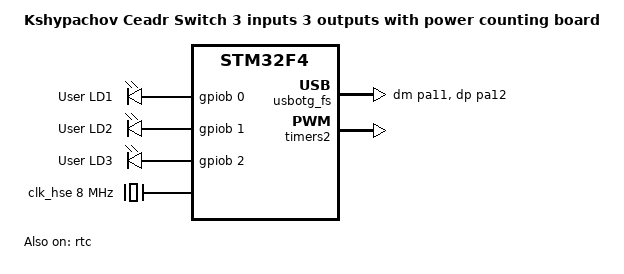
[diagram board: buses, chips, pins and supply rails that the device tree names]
/*
 * Copyright (c) 2017 Florian Vaussard, HEIG-VD
 *
 * SPDX-License-Identifier: Apache-2.0
 */

/dts-v1/;
#include <st/f4/stm32f411xe.dtsi>
#include <st/f4/stm32f411c(c-e)ux-pinctrl.dtsi>
//#include "arduino_r3_connector.dtsi"
#include <zephyr/dt-bindings/input/input-event-codes.h>

/ {
	model = "Kshypachov Ceadr Switch 3 inputs 3 outputs with power counting board";
	compatible = "kshypachov,cedar-switch-3in3out-power", "st,stm32f411ce", "st,stm32f4";

	chosen {
//		zephyr,console = &usart3;
//		zephyr,shell-uart = &usart3;
		zephyr,sram = &sram0;
		zephyr,flash = &flash0;
	};

	leds: leds {
		compatible = "gpio-leds";

		green_led_1: led_1 {
			gpios = <&gpiob 0 GPIO_ACTIVE_HIGH>;
			label = "User LD1";
		};

		blue_led_1: led_2 {
			gpios = <&gpiob 1 GPIO_ACTIVE_HIGH>;
			label = "User LD2";
		};

		red_led_1: led_3 {
			gpios = <&gpiob 2 GPIO_ACTIVE_HIGH>;
			label = "User LD3";
		};
	};

	aliases {
		led0 = &green_led_1;
		led1 = &blue_led_1;
		led2 = &red_led_1;
	};

};


//&spi2 {
//	status = "okay";
//	cs-gpios = <&gpiob 12 GPIO_ACTIVE_LOW>, <&gpioa 9 GPIO_ACTIVE_LOW>;
//	pinctrl-0 = <&spi2_sck_pb13 &spi2_miso_pb14 &spi2_mosi_pb15>;
//	pinctrl-names = "default";
//
//	w5500@0 {
//		compatible = "wiznet,w5500";
//		reg = <0>;
//		label = "ETH_W5500";
//		spi-max-frequency = <8000000>;
//		reset-gpios = <&gpioa 10 GPIO_ACTIVE_LOW>;
//		int-gpios = <&gpioa 0 GPIO_ACTIVE_LOW>;
//	};
//
//	flash@1 {
//		compatible = "jedec,spi-nor";
//		reg = <1>;
//		label = "W25Q64";
//		spi-max-frequency = <50000000>;
//	};
//};

&clk_lsi {
	status = "okay";
};

&clk_hse {
	hse-bypass;
	clock-frequency = <DT_FREQ_M(8)>; /* STLink 8MHz clock */
	status = "okay";
};

&pll {
	div-m = <8>;
	mul-n = <384>;
	div-p = <4>;
	div-q = <8>;
	clocks = <&clk_hse>;
	status = "okay";
};

&rcc {
	clocks = <&pll>;
	clock-frequency = <DT_FREQ_M(96)>;
	ahb-prescaler = <1>;
	apb1-prescaler = <2>;
	apb2-prescaler = <1>;
};


zephyr_udc0: &usbotg_fs {
	pinctrl-0 = <&usb_otg_fs_dm_pa11 &usb_otg_fs_dp_pa12>;
	pinctrl-names = "default";
	status = "okay";
};

&timers2 {
	status = "okay";

	pwm2: pwm {
		status = "okay";
		pinctrl-0 = <&tim2_ch1_pa0>;
		pinctrl-names = "default";
	};
};

&rtc {
	clocks = <&rcc STM32_CLOCK_BUS_APB1 0x10000000>,
		 <&rcc STM32_SRC_LSI RTC_SEL(2)>;
	status = "okay";
};
